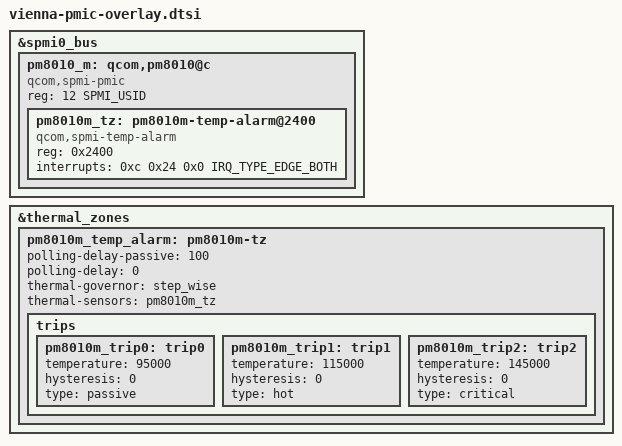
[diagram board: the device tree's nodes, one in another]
// SPDX-License-Identifier: BSD-3-Clause
 /*
  * Copyright (c) 2025 Qualcomm Innovation Center, Inc. All rights reserved.
  */

#include "pmw6100.dtsi"

&spmi0_bus {
	pm8010_m: qcom,pm8010@c {
		compatible = "qcom,spmi-pmic";
		reg = <12 SPMI_USID>;
		#address-cells = <1>;
		#size-cells = <0>;

		pm8010m_tz: pm8010m-temp-alarm@2400 {
			compatible = "qcom,spmi-temp-alarm";
			reg = <0x2400>;
			interrupts = <0xc 0x24 0x0 IRQ_TYPE_EDGE_BOTH>;
			#thermal-sensor-cells = <0>;
		};
	};
};

&thermal_zones {
	pm8010m_temp_alarm: pm8010m-tz {
		polling-delay-passive = <100>;
		polling-delay = <0>;
		thermal-governor = "step_wise";
		thermal-sensors = <&pm8010m_tz>;

		trips {
			pm8010m_trip0: trip0 {
				temperature = <95000>;
				hysteresis = <0>;
				type = "passive";
			};

			pm8010m_trip1: trip1 {
				temperature = <115000>;
				hysteresis = <0>;
				type = "hot";
			};

			pm8010m_trip2: trip2 {
				temperature = <145000>;
				hysteresis = <0>;
				type = "critical";
			};
		};
	};
};
